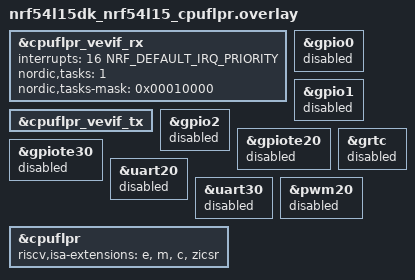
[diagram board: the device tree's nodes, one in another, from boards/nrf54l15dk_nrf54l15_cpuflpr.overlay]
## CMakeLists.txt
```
#
# Copyright (c) 2024 Nordic Semiconductor ASA
#
# SPDX-License-Identifier: LicenseRef-Nordic-5-Clause
#

cmake_minimum_required(VERSION 3.20.0)

find_package(Zephyr REQUIRED HINTS $ENV{ZEPHYR_BASE})
project(hpf_gpio)

hpf_assembly_install(app "${CMAKE_SOURCE_DIR}/src/hrt/hrt.c")

target_include_directories(app PRIVATE ../common)
target_sources(app PRIVATE src/main.c ../common/hpf_pin_map.c)

target_sources_ifdef(CONFIG_HPF_GPIO_BACKEND_ICMSG app PRIVATE src/backend/backend_icmsg.c)
target_sources_ifdef(CONFIG_HPF_GPIO_BACKEND_ICBMSG app PRIVATE src/backend/backend_icmsg.c)
target_sources_ifdef(CONFIG_HPF_GPIO_BACKEND_MBOX app PRIVATE  src/backend/backend_mbox.c)
```

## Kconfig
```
choice HPF_GPIO_BACKEND
	prompt "Backend"
	default HPF_GPIO_BACKEND_ICMSG

config HPF_GPIO_BACKEND_MBOX
	bool "mbox"

config HPF_GPIO_BACKEND_ICMSG
	bool "icmsg"
	select IPC_SERVICE

config HPF_GPIO_BACKEND_ICBMSG
	bool "icbmsg"
	select IPC_SERVICE

endchoice

config HPF_DEVELOPER_MODE
	bool "HPF developer mode"
	help
	  High Performance Framework developer mode.
	  If enabled, changes in HRT files will be included in build.
	  Otherwise, if there is a change in HRT that produces a different ASM file than
	  the provided one, build error is reported.

source "Kconfig.zephyr"
```

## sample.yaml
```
sample:
  name: HPF GPIO application
  description: HPF GPIO application
common:
  integration_platforms:
    - nrf54l15dk/nrf54l15/cpuflpr
tests:
  applications.hpf.gpio.mbox:
    build_only: true
    sysbuild: true
    platform_allow:
      - nrf54l15dk/nrf54l15/cpuflpr
      - nrf54lm20dk/nrf54lm20a/cpuflpr
      - nrf54lm20dk/nrf54lm20b/cpuflpr
      - nrf54lc10dk/nrf54lc10a/cpuflpr
      - nrf54lv10dk/nrf54lv10a/cpuflpr
      - nrf7120dk/nrf7120/cpuflpr
      - nrf9251dk/nrf9251/cpuflpr
    tags:
      - ci_build
      - sysbuild
      - gpio
      - ci_applications_hpf
    required_snippets:
      - hpf-gpio-mbox

  applications.hpf.gpio.icmsg:
    build_only: true
    sysbuild: true
    platform_allow:
      - nrf54l15dk/nrf54l15/cpuflpr
      - nrf54lm20dk/nrf54lm20a/cpuflpr
      - nrf54lm20dk/nrf54lm20b/cpuflpr
      - nrf54lc10dk/nrf54lc10a/cpuflpr
      - nrf54lv10dk/nrf54lv10a/cpuflpr
      - nrf7120dk/nrf7120/cpuflpr
      - nrf9251dk/nrf9251/cpuflpr
    tags:
      - ci_build
      - sysbuild
      - gpio
      - ci_applications_hpf
    required_snippets:
      - hpf-gpio-icmsg

  applications.hpf.gpio.icbmsg:
    sysbuild: true
    build_only: true
    platform_allow:
      - nrf54l15dk/nrf54l15/cpuflpr
      - nrf54lm20dk/nrf54lm20a/cpuflpr
      - nrf54lm20dk/nrf54lm20b/cpuflpr
      - nrf54lc10dk/nrf54lc10a/cpuflpr
      - nrf54lv10dk/nrf54lv10a/cpuflpr
      - nrf7120dk/nrf7120/cpuflpr
      - nrf9251dk/nrf9251/cpuflpr
    tags:
      - ci_build
      - sysbuild
      - gpio
      - ci_applications_hpf
    required_snippets:
      - hpf-gpio-icbmsg
```

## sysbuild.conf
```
SB_CONFIG_VPR_LAUNCHER=n
```

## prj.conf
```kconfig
# Single-threaded
CONFIG_MULTITHREADING=n
CONFIG_KERNEL_MEM_POOL=n
CONFIG_LOG=n

# Drivers and peripherals
CONFIG_I2C=n
CONFIG_WATCHDOG=n
CONFIG_GPIO=n
CONFIG_PINCTRL=n
CONFIG_SPI=n
CONFIG_SERIAL=n
CONFIG_FLASH=n
CONFIG_MBOX=y

# Power management
CONFIG_PM=n

# Interrupts
CONFIG_DYNAMIC_INTERRUPTS=n
CONFIG_IRQ_OFFLOAD=n
CONFIG_GEN_SW_ISR_TABLE=n

# Memory protection
CONFIG_THREAD_STACK_INFO=n
CONFIG_THREAD_CUSTOM_DATA=n
CONFIG_FPU=n

# Boot
CONFIG_BOOT_BANNER=n
CONFIG_NCS_BOOT_BANNER=n

# Console
CONFIG_CONSOLE=n
CONFIG_UART_CONSOLE=n
CONFIG_STDOUT_CONSOLE=n
CONFIG_PRINTK=n
CONFIG_EARLY_CONSOLE=n

# Build
CONFIG_SIZE_OPTIMIZATIONS=y

# No timer support in the kernel
CONFIG_SYS_CLOCK_EXISTS=n

CONFIG_COMMON_LIBC_MALLOC=n
```

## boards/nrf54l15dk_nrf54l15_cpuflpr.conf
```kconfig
# Single-threaded
CONFIG_MULTITHREADING=n
CONFIG_KERNEL_MEM_POOL=n
CONFIG_LOG=n

# Drivers and peripherals
CONFIG_I2C=n
CONFIG_WATCHDOG=n
CONFIG_GPIO=n
CONFIG_PINCTRL=n
CONFIG_SPI=n
CONFIG_SERIAL=n
CONFIG_FLASH=n

# Power management
CONFIG_PM=n

# Interrupts
CONFIG_DYNAMIC_INTERRUPTS=n
CONFIG_IRQ_OFFLOAD=n
CONFIG_GEN_SW_ISR_TABLE=n

# Memory protection
CONFIG_THREAD_STACK_INFO=n
CONFIG_THREAD_CUSTOM_DATA=n
CONFIG_FPU=n

# Boot
CONFIG_BOOT_BANNER=n
CONFIG_NCS_BOOT_BANNER=n

# Console
CONFIG_CONSOLE=n
CONFIG_UART_CONSOLE=n
CONFIG_STDOUT_CONSOLE=n
CONFIG_PRINTK=n
CONFIG_EARLY_CONSOLE=n

# Build
CONFIG_SIZE_OPTIMIZATIONS=y

# No timer support in the kernel
CONFIG_SYS_CLOCK_EXISTS=n

CONFIG_OUTPUT_DISASSEMBLY=y
CONFIG_COMMON_LIBC_MALLOC=n
```

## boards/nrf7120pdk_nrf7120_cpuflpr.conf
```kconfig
# Minimal single-threaded config for nRF7120 FLPR HPF GPIO image

# Single-threaded
CONFIG_MULTITHREADING=n
CONFIG_KERNEL_MEM_POOL=n
CONFIG_LOG=n

# Drivers and peripherals
CONFIG_I2C=n
CONFIG_WATCHDOG=n
CONFIG_GPIO=n
CONFIG_PINCTRL=n
CONFIG_SPI=n
CONFIG_SERIAL=n
CONFIG_FLASH=n

# Power management
CONFIG_PM=n

# Interrupts
CONFIG_DYNAMIC_INTERRUPTS=n
CONFIG_IRQ_OFFLOAD=n
CONFIG_GEN_SW_ISR_TABLE=n

# Memory protection
CONFIG_THREAD_STACK_INFO=n
CONFIG_THREAD_CUSTOM_DATA=n
CONFIG_FPU=n

# Boot
CONFIG_BOOT_BANNER=n
CONFIG_NCS_BOOT_BANNER=n

# Console
CONFIG_CONSOLE=n
CONFIG_UART_CONSOLE=n
CONFIG_STDOUT_CONSOLE=n
CONFIG_PRINTK=n
CONFIG_EARLY_CONSOLE=n

# Build
CONFIG_SIZE_OPTIMIZATIONS=y

# No timer support in the kernel
CONFIG_SYS_CLOCK_EXISTS=n

CONFIG_OUTPUT_DISASSEMBLY=y
CONFIG_COMMON_LIBC_MALLOC=n
```

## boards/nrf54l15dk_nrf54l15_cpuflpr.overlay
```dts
/*
 * Copyright (c) 2024 Nordic Semiconductor ASA
 *
 * SPDX-License-Identifier: LicenseRef-Nordic-5-Clause
 */

&cpuflpr_vevif_rx {
	interrupts = <16 NRF_DEFAULT_IRQ_PRIORITY>;
	nordic,tasks = <1>;
	nordic,tasks-mask = <0x00010000>;
	status = "okay";
};

&cpuflpr_vevif_tx {
	status = "okay";
};

&gpio0 {
	status = "disabled";
};

&gpio1 {
	status = "disabled";
};

&gpio2 {
	status = "disabled";
};

&gpiote20 {
	status = "disabled";
};

&gpiote30 {
	status = "disabled";
};

&grtc {
	status = "disabled";
};

&uart20 {
	status = "disabled";
};

&uart30 {
	status = "disabled";
};

&pwm20 {
	status = "disabled";
};

/* The committed HRT assembly is generated without the bit-manipulation
 * and compressed extensions that the SoC devicetree enables.
 */
&cpuflpr {
	riscv,isa-extensions = "e", "m", "c", "zicsr";
};
```

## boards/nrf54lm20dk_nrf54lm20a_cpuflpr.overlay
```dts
/*
 * Copyright (c) 2025 Nordic Semiconductor ASA
 *
 * SPDX-License-Identifier: LicenseRef-Nordic-5-Clause
 */

&cpuflpr_vevif_rx {
	interrupts = <16 NRF_DEFAULT_IRQ_PRIORITY>;
	nordic,tasks = <1>;
	nordic,tasks-mask = <0x00010000>;
	status = "okay";
};

&cpuflpr_vevif_tx {
	status = "okay";
};

&gpio0 {
	status = "disabled";
};

&gpio1 {
	status = "disabled";
};

&gpio2 {
	status = "disabled";
};

&gpiote20 {
	status = "disabled";
};

&gpiote30 {
	status = "disabled";
};

&grtc {
	status = "disabled";
};

&uart20 {
	status = "disabled";
};

&uart30 {
	status = "disabled";
};

&pwm20 {
	status = "disabled";
};

/* The committed HRT assembly is generated without the bit-manipulation
 * and compressed extensions that the SoC devicetree enables.
 */
&cpuflpr {
	riscv,isa-extensions = "e", "m", "c", "zicsr";
};
```

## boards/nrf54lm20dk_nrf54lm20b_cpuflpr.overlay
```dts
/*
 * Copyright (c) 2026 Nordic Semiconductor ASA
 *
 * SPDX-License-Identifier: LicenseRef-Nordic-5-Clause
 */

#include "nrf54lm20dk_nrf54lm20a_cpuflpr.overlay"

/* The committed HRT assembly is generated without the bit-manipulation
 * and compressed extensions that the SoC devicetree enables.
 */
&cpuflpr {
	riscv,isa-extensions = "e", "m", "c", "zicsr";
};
```

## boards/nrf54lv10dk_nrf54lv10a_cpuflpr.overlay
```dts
/*
 * Copyright (c) 2026 Nordic Semiconductor ASA
 *
 * SPDX-License-Identifier: LicenseRef-Nordic-5-Clause
 */

&cpuflpr_vevif_rx {
	status = "okay";
	interrupts = <16 NRF_DEFAULT_IRQ_PRIORITY>;
	nordic,tasks = <1>;
	nordic,tasks-mask = <0x00010000>;
};

&cpuflpr_vevif_tx {
	status = "okay";
};

&gpio0 {
	status = "disabled";
};

&gpio1 {
	status = "disabled";
};

&gpiote20 {
	status = "disabled";
};

&gpiote30 {
	status = "disabled";
};

&grtc {
	status = "disabled";
};

&uart20 {
	status = "disabled";
};

&uart30 {
	status = "disabled";
};
```

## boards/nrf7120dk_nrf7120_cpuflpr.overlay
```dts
/*
 * Copyright (c) 2026 Nordic Semiconductor ASA
 *
 * SPDX-License-Identifier: LicenseRef-Nordic-5-Clause
 */

&cpuflpr_vevif_rx {
	status = "okay";
	interrupts = <16 NRF_DEFAULT_IRQ_PRIORITY>;
	nordic,tasks = <1>;
	nordic,tasks-mask = <0x00010000>;
};

&cpuflpr_vevif_tx {
	status = "okay";
};

&gpio0 {
	status = "disabled";
};

&gpio1 {
	status = "disabled";
};

&gpio2 {
	status = "disabled";
};

&gpiote20 {
	status = "disabled";
};

&gpiote30 {
	status = "disabled";
};

&grtc {
	status = "disabled";
};

&uart20 {
	status = "disabled";
};

&uart21 {
	status = "okay";
};

&pwm20 {
	status = "disabled";
};
```

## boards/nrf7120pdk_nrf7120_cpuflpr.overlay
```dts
/*
 * Copyright (c) 2025 Nordic Semiconductor ASA
 *
 * SPDX-License-Identifier: LicenseRef-Nordic-5-Clause
 */

&cpuflpr_vevif_rx {
	status = "okay";
	interrupts = <16 NRF_DEFAULT_IRQ_PRIORITY>;
	nordic,tasks = <1>;
	nordic,tasks-mask = <0x00010000>;
};

&cpuflpr_vevif_tx {
	status = "okay";
};

&gpio0 {
	status = "disabled";
};

&gpio1 {
	status = "disabled";
};

&gpio2 {
	status = "disabled";
};

&gpiote20 {
	status = "disabled";
};

&gpiote30 {
	status = "disabled";
};

&grtc {
	status = "disabled";
};

&uart20 {
	status = "disabled";
};

&uart30 {
	status = "okay";
};

&pwm20 {
	status = "disabled";
};
```

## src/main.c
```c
/*
 * Copyright (c) 2024 Nordic Semiconductor ASA
 *
 * SPDX-License-Identifier: LicenseRef-Nordic-5-Clause
 */

#include "./backend/backend.h"
#include "./hrt/hrt.h"

#include <zephyr/kernel.h>
#include <zephyr/sys/__assert.h>
#include <zephyr/drivers/gpio.h>
#include <zephyr/dt-bindings/gpio/nordic-nrf-gpio.h>
#include <drivers/gpio/hpf_gpio.h>
#include <hal/nrf_vpr_csr.h>
#include <hal/nrf_vpr_csr_vio.h>
#include <haly/nrfy_gpio.h>
#include <helpers/nrfx_vpr_vio_pins.h>

#define HRT_IRQ_PRIORITY          2
#define HRT_VEVIF_IDX_GPIO_CLEAR  17
#define HRT_VEVIF_IDX_GPIO_SET    18
#define HRT_VEVIF_IDX_GPIO_TOGGLE 19
#define HRT_VEVIF_IDX_GPIO_SET_MASKED 21

#define VEVIF_IRQN(vevif) VEVIF_IRQN_1(vevif)
#define VEVIF_IRQN_1(vevif) VPRCLIC_##vevif##_IRQn

volatile uint16_t irq_arg;
volatile uint16_t irq_arg2;

BUILD_ASSERT(NRFX_VPR_VIO_MAPPING_DEFINED_CHECK(NRF_VPR_IDX_FLPR),
	     "VIO pin mapping not defined for FLPR");

#define VIO_INDEX_INVALID UINT8_MAX
#define VIO_PIN_MASK_INVALID UINT16_MAX

#define VIO_PORT_COUNT NRFX_VPR_VIO_MAPPED_PORT_COUNT_GET(NRF_VPR_IDX_FLPR)
BUILD_ASSERT(VIO_PORT_COUNT >= 1);

/*
 * Create table of VIO indices, if multiple pins are routed to the same index the index will appear
 * more than once.
 */
#define GEN_VIO_PIN_INDEX(vpr_idx, port, pin) NRFX_VPR_VIO_PIN_INDEX_GET(vpr_idx, port, pin)
static const uint8_t vio_pin_vio_index[] = {
	NRFX_VPR_VIO_FOR_EACH_PIN(NRF_VPR_IDX_FLPR, GEN_VIO_PIN_INDEX, (,))
};

/* Create table of GPIO pins (matches the VIO indices). */
#define GEN_VIO_PIN_NUM(vpr_idx, port, pin)   (pin)
static const uint8_t vio_pin_gpio_num[] = {
	NRFX_VPR_VIO_FOR_EACH_PIN(NRF_VPR_IDX_FLPR, GEN_VIO_PIN_NUM, (,))
};
BUILD_ASSERT(ARRAY_SIZE(vio_pin_gpio_num) == ARRAY_SIZE(vio_pin_vio_index));

#if VIO_PORT_COUNT > 1

/* Create table of GPIO ports (matches the VIO indices). */
#define GEN_VIO_PIN_PORT(vpr_idx, port, pin) (port)
static const uint8_t vio_pin_gpio_port[] = {
	NRFX_VPR_VIO_FOR_EACH_PIN(NRF_VPR_IDX_FLPR, GEN_VIO_PIN_PORT, (,))
};
BUILD_ASSERT(ARRAY_SIZE(vio_pin_gpio_port) == ARRAY_SIZE(vio_pin_vio_index));

#else /* VIO_PORT_COUNT == 1 */

#define VIO_PORT _NRFX_GET_ARG1(_NRFX_VPR_VIO_PORT_LIST_GET(NRF_VPR_IDX_FLPR))

#endif /* VIO_PORT_COUNT > 1 */

static uint8_t gpio_pin_port_to_vio_index(uint8_t port, uint16_t pin)
{
#if VIO_PORT_COUNT <= 1
	if (port != VIO_PORT) {
		return VIO_INDEX_INVALID;
	}
#endif

	for (size_t i = 0; i < ARRAY_SIZE(vio_pin_gpio_num); i++) {
#if VIO_PORT_COUNT > 1
		if (vio_pin_gpio_port[i] != port) {
			continue;
		}
#endif
		if (vio_pin_gpio_num[i] == pin) {
			return vio_pin_vio_index[i];
		}
	}

	return VIO_INDEX_INVALID;
}

static uint16_t gpio_pin_mask_to_vio_mask(uint8_t port, uint32_t gpio_pin_mask)
{
	uint16_t vio_mask = 0;
	uint32_t accessible_mask = 0;

#if VIO_PORT_COUNT == 1
	__ASSERT_NO_MSG(port == VIO_PORT);
#endif

	for (size_t i = 0; i < ARRAY_SIZE(vio_pin_gpio_num); i++) {
#if VIO_PORT_COUNT > 1
		if (vio_pin_gpio_port[i] != port) {
			continue;
		}
#endif
		accessible_mask |= BIT(vio_pin_gpio_num[i]);
		if (gpio_pin_mask & BIT(vio_pin_gpio_num[i])) {
			vio_mask |= BIT(vio_pin_vio_index[i]);
		}
	}

	/* Reject the request if any pin in the mask cannot be accessed by the VIO. */
	if ((gpio_pin_mask & ~accessible_mask) != 0) {
		return VIO_PIN_MASK_INVALID;
	}

	return vio_mask;
}

static nrf_gpio_pin_pull_t get_pull(gpio_flags_t flags)
{
	if (flags & GPIO_PULL_UP) {
		return NRF_GPIO_PIN_PULLUP;
	} else if (flags & GPIO_PULL_DOWN) {
		return NRF_GPIO_PIN_PULLDOWN;
	}

	return NRF_GPIO_PIN_NOPULL;
}

static int gpio_hpf_pin_configure(uint8_t port, uint16_t pin, uint32_t flags)
{
	uint8_t pin_vio_index = gpio_pin_port_to_vio_index(port, pin);

	if (pin_vio_index == VIO_INDEX_INVALID) {
		return -EINVAL;
	}
	uint32_t abs_pin = NRF_GPIO_PIN_MAP(port, pin);
	nrf_gpio_pin_pull_t pull = get_pull(flags);
	nrf_gpio_pin_drive_t drive;

	switch (flags & (NRF_GPIO_DRIVE_MSK | GPIO_OPEN_DRAIN)) {
	case NRF_GPIO_DRIVE_S0S1:
		drive = NRF_GPIO_PIN_S0S1;
		break;
	case NRF_GPIO_DRIVE_S0H1:
		drive = NRF_GPIO_PIN_S0H1;
		break;
	case NRF_GPIO_DRIVE_H0S1:
		drive = NRF_GPIO_PIN_H0S1;
		break;
	case NRF_GPIO_DRIVE_H0H1:
		drive = NRF_GPIO_PIN_H0H1;
		break;
	case NRF_GPIO_DRIVE_S0 | GPIO_OPEN_DRAIN:
		drive = NRF_GPIO_PIN_S0D1;
		break;
	case NRF_GPIO_DRIVE_H0 | GPIO_OPEN_DRAIN:
		drive = NRF_GPIO_PIN_H0D1;
		break;
	case NRF_GPIO_DRIVE_S1 | GPIO_OPEN_SOURCE:
		drive = NRF_GPIO_PIN_D0S1;
		break;
	case NRF_GPIO_DRIVE_H1 | GPIO_OPEN_SOURCE:
		drive = NRF_GPIO_PIN_D0H1;
		break;
	default:
		return -EINVAL;
	}

	nrf_gpio_pin_dir_t dir =
		(flags & GPIO_OUTPUT) ? NRF_GPIO_PIN_DIR_OUTPUT : NRF_GPIO_PIN_DIR_INPUT;
	nrf_gpio_pin_input_t input =
		(flags & GPIO_INPUT) ? NRF_GPIO_PIN_INPUT_CONNECT : NRF_GPIO_PIN_INPUT_DISCONNECT;

	nrfy_gpio_reconfigure(abs_pin, &dir, &input, &pull, &drive, NULL);

#if NRF_GPIO_HAS_SEL
	nrfy_gpio_pin_control_select(abs_pin, NRF_GPIO_PIN_SEL_VPR);
	/*
	 * If the device does not support selecting VIO pin using the command above, the pinst need
	 * to be routed to the VPR using UICR registered configured in devicetree on the app core.
	 */
#endif

	if (dir == NRF_GPIO_PIN_DIR_OUTPUT) {
		nrf_vpr_csr_vio_dir_set(nrf_vpr_csr_vio_dir_get() | (BIT(pin_vio_index)));
	}

	if (flags & GPIO_OUTPUT_INIT_HIGH) {
		uint16_t outs = nrf_vpr_csr_vio_out_get();

		nrf_vpr_csr_vio_out_set(outs | (BIT(pin_vio_index)));
	} else if (flags & GPIO_OUTPUT_INIT_LOW) {
		uint16_t outs = nrf_vpr_csr_vio_out_get();

		nrf_vpr_csr_vio_out_set(outs & ~(BIT(pin_vio_index)));
	}

	return 0;
}

void process_packet(hpf_gpio_data_packet_t *packet)
{
	if (packet->opcode == HPF_GPIO_PIN_CONFIGURE) {
		int ret = gpio_hpf_pin_configure(packet->port, packet->pin, packet->flags);

		/* Prevent warnings when asserts are disabled. */
		(void)ret;
		__ASSERT_NO_MSG(ret == 0);
	} else {
		uint16_t vio_mask = gpio_pin_mask_to_vio_mask(packet->port, packet->pin);

		__ASSERT_NO_MSG(vio_mask != VIO_PIN_MASK_INVALID);

		irq_arg = vio_mask;
		switch (packet->opcode) {
		case HPF_GPIO_PIN_CLEAR:
			nrf_vpr_clic_int_pending_set(NRF_VPRCLIC,
						     VEVIF_IRQN(HRT_VEVIF_IDX_GPIO_CLEAR));
			break;
		case HPF_GPIO_PIN_SET:
			nrf_vpr_clic_int_pending_set(NRF_VPRCLIC,
						     VEVIF_IRQN(HRT_VEVIF_IDX_GPIO_SET));
			break;
		case HPF_GPIO_PIN_TOGGLE:
			nrf_vpr_clic_int_pending_set(NRF_VPRCLIC,
						     VEVIF_IRQN(HRT_VEVIF_IDX_GPIO_TOGGLE));
			break;
		case HPF_GPIO_PORT_SET_MASKED:
			irq_arg2 = gpio_pin_mask_to_vio_mask(packet->port,
							     packet->flags & packet->pin);
			nrf_vpr_clic_int_pending_set(NRF_VPRCLIC,
						     VEVIF_IRQN(HRT_VEVIF_IDX_GPIO_SET_MASKED));
			break;
		default:
			break;
		}
	}
}

#define HRT_CONNECT(vevif, handler)                                            \
	IRQ_DIRECT_CONNECT(vevif, HRT_IRQ_PRIORITY, handler, 0);               \
	nrf_vpr_clic_int_enable_set(NRF_VPRCLIC, VEVIF_IRQN(vevif), true)


__attribute__ ((interrupt)) void hrt_handler_clear_bits(void)
{
	hrt_clear_bits();
}

__attribute__ ((interrupt)) void hrt_handler_set_bits(void)
{
	hrt_set_bits();
}

__attribute__ ((interrupt)) void hrt_handler_toggle_bits(void)
{
	hrt_toggle_bits();
}

__attribute__ ((interrupt)) void hrt_handler_set_masked_bits(void)
{
	hrt_set_masked_bits();
}

int main(void)
{
	int ret = 0;

	HRT_CONNECT(HRT_VEVIF_IDX_GPIO_CLEAR, hrt_handler_clear_bits);
	HRT_CONNECT(HRT_VEVIF_IDX_GPIO_SET, hrt_handler_set_bits);
	HRT_CONNECT(HRT_VEVIF_IDX_GPIO_TOGGLE, hrt_handler_toggle_bits);
	HRT_CONNECT(HRT_VEVIF_IDX_GPIO_SET_MASKED, hrt_handler_set_masked_bits);

	nrf_vpr_csr_rtperiph_enable_set(true);

	ret = backend_init(process_packet);
	if (ret < 0) {
		return 0;
	}

	while (true) {
		k_cpu_idle();
	}

	return 0;
}
```
